# MDR32F1QI register map
Vendor: Milandr; File version: 1.0
CPU: CM1 r0p0, little endian, no MPU, no FPU, 3 interrupt priority bits
Registers are 32-bit, read-write, reset 0x0 unless marked. A register's access mark holds for its fields unless they carry their own. Offsets are from the block's base; [hi:lo] are bit positions; {n}, {i} and the like mark numbered series.

## MDR_DAC — DAC
Base 0x40090000; register names take the prefix MDR_DAC_
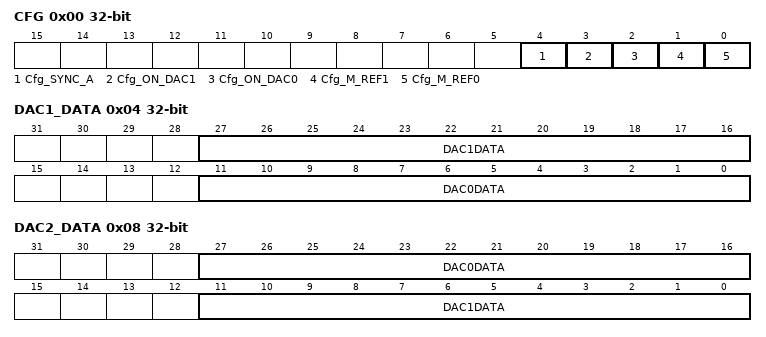
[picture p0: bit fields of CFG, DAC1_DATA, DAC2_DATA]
0x00 CFG — DAC Configuration Register
  [4] Cfg_SYNC_A, [3] Cfg_ON_DAC1, [2] Cfg_ON_DAC0, [1] Cfg_M_REF1, [0] Cfg_M_REF0
0x04 DAC1_DATA
  [27:16] DAC1DATA, [11:0] DAC0DATA
0x08 DAC2_DATA
  [27:16] DAC0DATA, [11:0] DAC1DATA

## MDR_PORTA — PORTA
Base 0x400A8000; register names take the prefix MDR_PORTA_
Same registers: MDR_PORTB 0x400B0000 (register names take the prefix MDR_PORTB_), MDR_PORTC 0x400B8000 (register names take the prefix MDR_PORTC_), MDR_PORTD 0x400C0000 (register names take the prefix MDR_PORTD_), MDR_PORTE 0x400C8000 (register names take the prefix MDR_PORTE_), MDR_PORTF 0x400E8000 (register names take the prefix MDR_PORTF_)
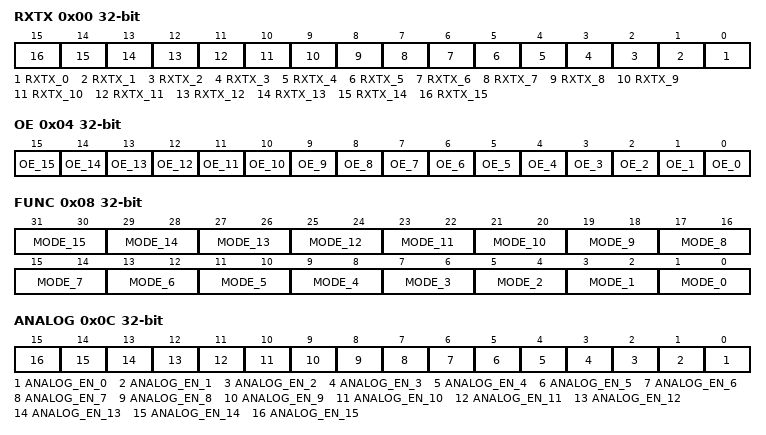
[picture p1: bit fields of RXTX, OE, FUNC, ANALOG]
0x00 RXTX — PORT Data Register
  [n] RXTX_{n} (n=0..15)
0x04 OE — PORT Output Enable Register
  [n] OE_{n} (n=0..15)
0x08 FUNC — PORT Function Register
  [2n+1:2n] MODE_{n} (n=0..15)
0x0C ANALOG — PORT Analog Function Register
  [n] ANALOG_EN_{n} (n=0..15)
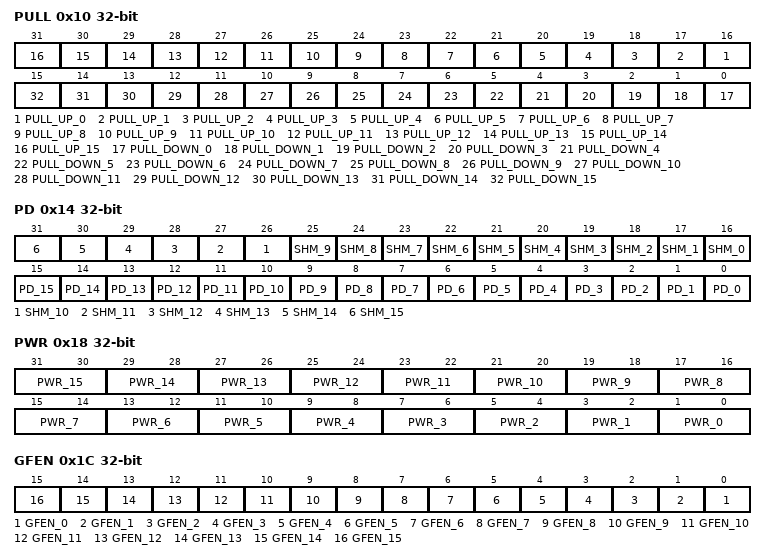
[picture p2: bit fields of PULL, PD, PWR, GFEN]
0x10 PULL — PORT Pull Up/Down Register
  [n+16] PULL_UP_{n} (n=0..15), [n] PULL_DOWN_{n} (n=0..15)
0x14 PD — PORT Driver Mode Register
  [n+16] SHM_{n} (n=0..15), [n] PD_{n} (n=0..15)
0x18 PWR — PORT Power Register
  [2n+1:2n] PWR_{n} (n=0..15)
0x1C GFEN — PORT Filter Configuration Register
  [n] GFEN_{n} (n=0..15)
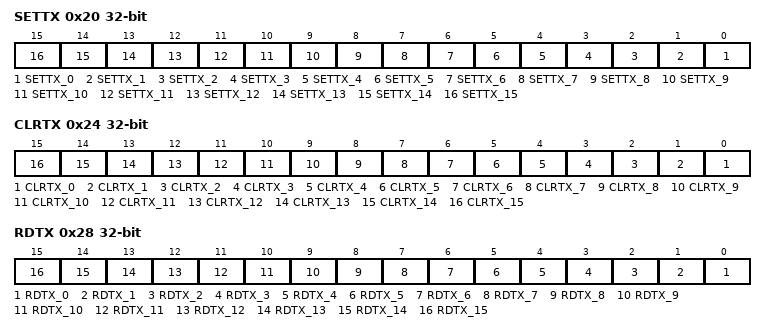
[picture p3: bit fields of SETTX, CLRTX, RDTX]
0x20 SETTX — Set Pin in function PORT
  [n] SETTX_{n} (n=0..15)
0x24 CLRTX — Clear Pin in function PORT
  [n] CLRTX_{n} (n=0..15)
0x28 RDTX ro — Read Pin out in function PORT
  [n] RDTX_{n} rw (n=0..15)

## MDR_ARINC429R — ARINC429R
Base 0x400D0000; register names take the prefix MDR_ARINC429R_
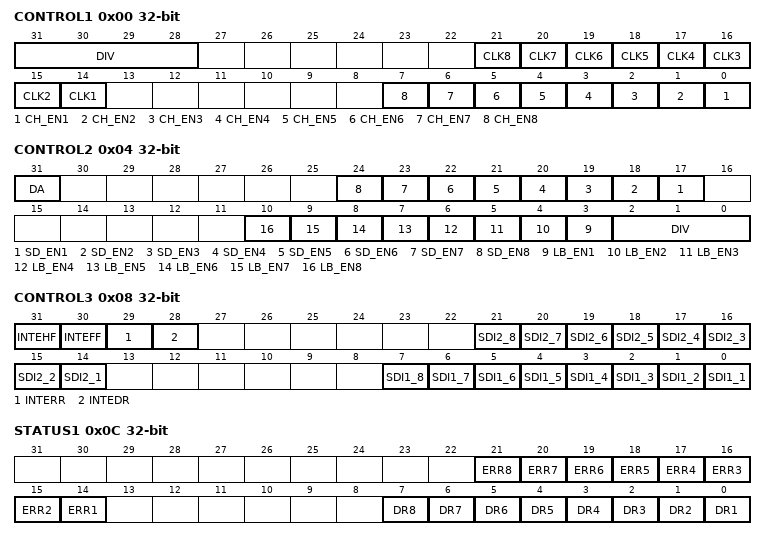
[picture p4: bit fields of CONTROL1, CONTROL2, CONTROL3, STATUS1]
0x00 CONTROL1 — ARINC429R Control1 register
  [31:28] DIV, [n+13] CLK{n} (n=1..8), [n-1] CH_EN{n} (n=1..8)
0x04 CONTROL2 — ARINC429R Control2 register
  [31] DA, [n+16] SD_EN{n} (n=1..8), [n+2] LB_EN{n} (n=1..8), [2:0] DIV
0x08 CONTROL3 — ARINC429R Control3 register
  [31] INTEHF, [30] INTEFF, [29] INTERR, [28] INTEDR, [n+13] SDI2_{n} (n=1..8), [n-1] SDI1_{n} (n=1..8)
0x0C STATUS1 — ARINC429R Status 1 register
  [n+13] ERR{n} (n=1..8), [n-1] DR{n} (n=1..8)
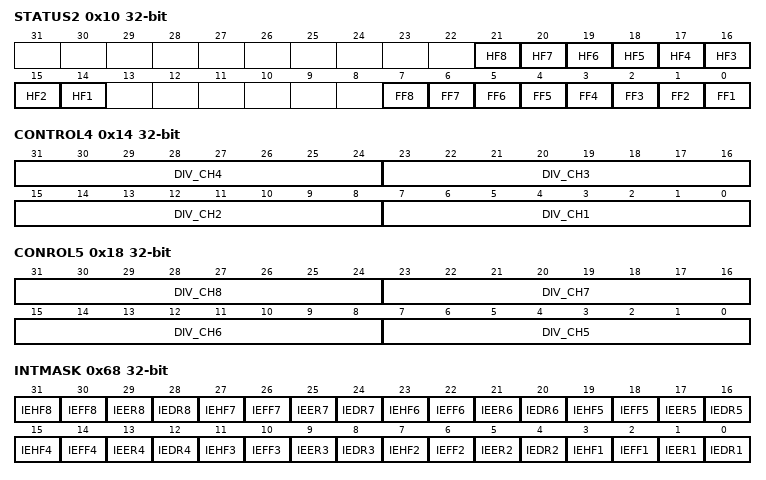
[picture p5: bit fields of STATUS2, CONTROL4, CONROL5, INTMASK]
0x10 STATUS2 — ARINC429R Status 2 register
  [n+13] HF{n} (n=1..8), [n-1] FF{n} (n=1..8)
0x14 CONTROL4 — ARINC429R Control 4 register
  [8n-1:8n-8] DIV_CH{n} (n=1..4)
0x18 CONROL5 — ARINC429R Control 5 register
  [8n-33:8n-40] DIV_CH{n} (n=5..8)
0x1C CHANNEL — ARINC429R Channel register
  [3:0] CHAN
0x20 LABLE — ARINC429R Lable register
0x24 DATA_R — ARINC429R Data_r register
{0x2C+4i} DATA_R{i} (i=1..8) — ARINC429R Data {i} register
0x68 INTMASK — ARINC429R interrupt mask register
  [4n-1] IEHF{n} (n=1..8), [4n-2] IEFF{n} (n=1..8), [4n-3] IEER{n} (n=1..8), [4n-4] IEDR{n} (n=1..8)

## MDR_BKP — BACKUP
Base 0x400D8000; register names take the prefix MDR_BKP_
{0x0+4i} REG_{i:02} (i=0..9) — Backup Register {i}
  [31:0] BKP_REG
0x28 REG_0A — Backup Register 10
  [31:0] BKP_REG
0x2C REG_0B — Backup Register 11
  [31:0] BKP_REG
0x30 REG_0C — Backup Register 12
  [31:0] BKP_REG
0x34 REG_0D — Backup Register 13
  [31:0] BKP_REG
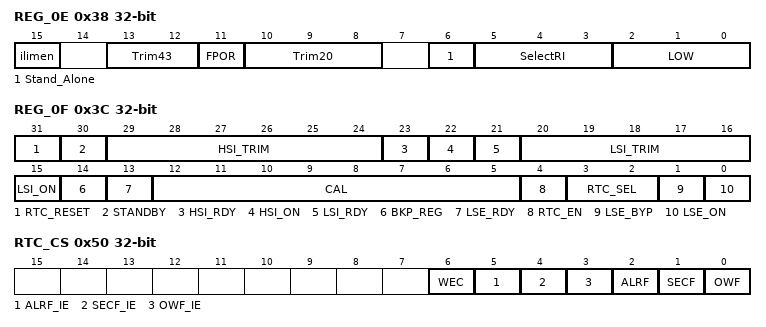
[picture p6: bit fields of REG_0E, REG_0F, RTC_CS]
0x38 REG_0E — Backup Register 14
  [15] ilimen, [13:12] Trim43, [11] FPOR, [10:8] Trim20, [6] Stand_Alone, [5:3] SelectRI, [2:0] LOW
0x3C REG_0F — Backup Register 15
  [31] RTC_RESET, [30] STANDBY, [29:24] HSI_TRIM, [23] HSI_RDY, [22] HSI_ON, [21] LSI_RDY, [20:16] LSI_TRIM, [15] LSI_ON, [14] BKP_REG, [13] LSE_RDY, [12:5] CAL, [4] RTC_EN, [3:2] RTC_SEL, [1] LSE_BYP, [0] LSE_ON
0x40 RTC_CNT — Realtime Clock Counter Register
0x44 RTC_DIV — Realtime Prescaler Counter Register
  [19:0] RTC_DIV
0x48 RTC_PRL — Realtime Prescaler Auto-Reload Value Register
  [19:0] RTC_PRL
0x4C RTC_ALRM — Realtime Alarm Register
0x50 RTC_CS — Backup Realtime clock Register
  [6] WEC, [5] ALRF_IE, [4] SECF_IE, [3] OWF_IE, [2] ALRF, [1] SECF, [0] OWF

## MDR_ARINC429T — ARINC429T
Base 0x400E0000; register names take the prefix MDR_ARINC429T_
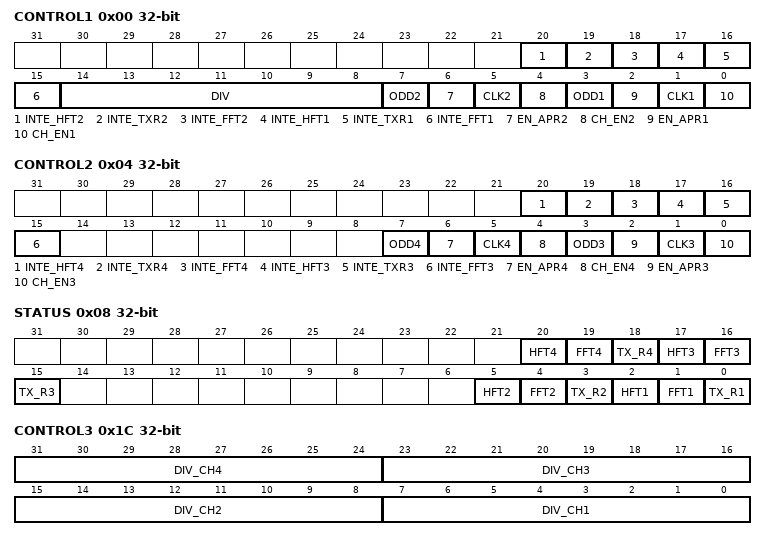
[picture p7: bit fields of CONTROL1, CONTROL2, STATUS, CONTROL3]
0x00 CONTROL1
  [20] INTE_HFT2, [19] INTE_TXR2, [18] INTE_FFT2, [17] INTE_HFT1, [16] INTE_TXR1, [15] INTE_FFT1, [14:8] DIV, [7] ODD2, [6] EN_APR2, [5] CLK2, [4] CH_EN2, [3] ODD1, [2] EN_APR1, [1] CLK1, [0] CH_EN1
0x04 CONTROL2
  [20] INTE_HFT4, [19] INTE_TXR4, [18] INTE_FFT4, [17] INTE_HFT3, [16] INTE_TXR3, [15] INTE_FFT3, [7] ODD4, [6] EN_APR4, [5] CLK4, [4] CH_EN4, [3] ODD3, [2] EN_APR3, [1] CLK3, [0] CH_EN3
0x08 STATUS
  [20] HFT4, [19] FFT4, [18] TX_R4, [17] HFT3, [16] FFT3, [15] TX_R3, [5] HFT2, [4] FFT2, [3] TX_R2, [2] HFT1, [1] FFT1, [0] TX_R1
{0x8+4i} DATA{i}_T (i=1..4)
0x1C CONTROL3
  [8n-1:8n-8] DIV_CH{n} (n=1..4)

## MDR_EBC — EBC
Base 0x400F0000; register names take the prefix MDR_EBC_
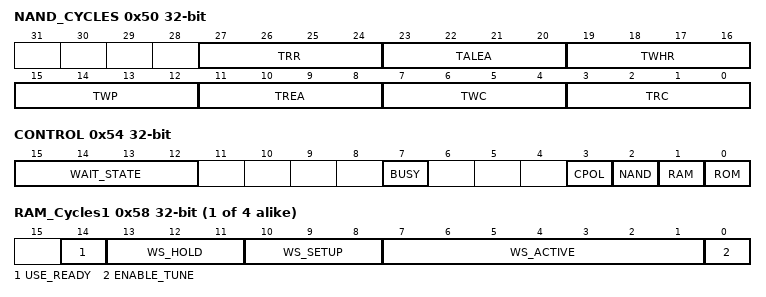
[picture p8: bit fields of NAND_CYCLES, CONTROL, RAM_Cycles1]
0x50 NAND_CYCLES — EBC NAND Timing Register
  [27:24] TRR, [23:20] TALEA, [19:16] TWHR, [15:12] TWP, [11:8] TREA, [7:4] TWC, [3:0] TRC
0x54 CONTROL — EBC Control Register
  [15:12] WAIT_STATE, [7] BUSY, [3] CPOL, [2] NAND, [1] RAM, [0] ROM
{0x54+4i} RAM_Cycles{i} (i=1..4)
  [14] USE_READY, [13:11] WS_HOLD, [10:8] WS_SETUP, [7:1] WS_ACTIVE, [0] ENABLE_TUNE

## MDR_Ethernet — Ethernet
Base 0x30000000; register names take the prefix MDR_Ethernet_
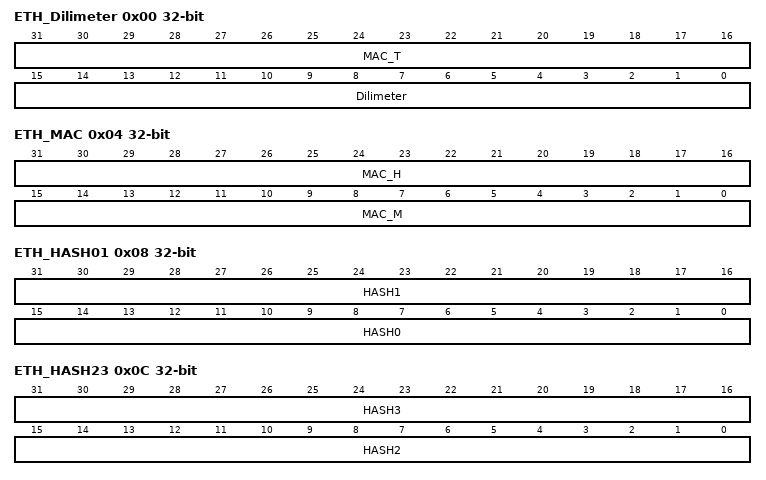
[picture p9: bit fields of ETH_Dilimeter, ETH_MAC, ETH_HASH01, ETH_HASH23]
0x00 ETH_Dilimeter
  [31:16] MAC_T, [15:0] Dilimeter
0x04 ETH_MAC
  [31:16] MAC_H, [15:0] MAC_M
0x08 ETH_HASH01
  [31:16] HASH1, [15:0] HASH0
0x0C ETH_HASH23
  [31:16] HASH3, [15:0] HASH2
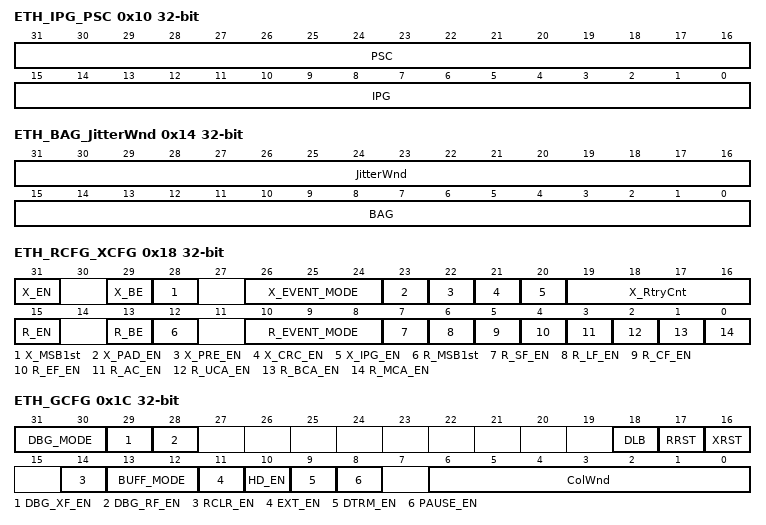
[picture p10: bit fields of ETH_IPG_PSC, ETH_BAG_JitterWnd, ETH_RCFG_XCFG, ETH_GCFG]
0x10 ETH_IPG_PSC
  [31:16] PSC, [15:0] IPG
0x14 ETH_BAG_JitterWnd
  [31:16] JitterWnd, [15:0] BAG
0x18 ETH_RCFG_XCFG
  [31] X_EN, [29] X_BE, [28] X_MSB1st, [26:24] X_EVENT_MODE, [23] X_PAD_EN, [22] X_PRE_EN, [21] X_CRC_EN, [20] X_IPG_EN, [19:16] X_RtryCnt, [15] R_EN, [13] R_BE, [12] R_MSB1st, [10:8] R_EVENT_MODE, [7] R_SF_EN, [6] R_LF_EN, [5] R_CF_EN, [4] R_EF_EN, [3] R_AC_EN, [2] R_UCA_EN, [1] R_BCA_EN, [0] R_MCA_EN
0x1C ETH_GCFG
  [31:30] DBG_MODE, [29] DBG_XF_EN, [28] DBG_RF_EN, [18] DLB, [17] RRST, [16] XRST, [14] RCLR_EN, [13:12] BUFF_MODE, [11] EXT_EN, [10] HD_EN, [9] DTRM_EN, [8] PAUSE_EN, [6:0] ColWnd
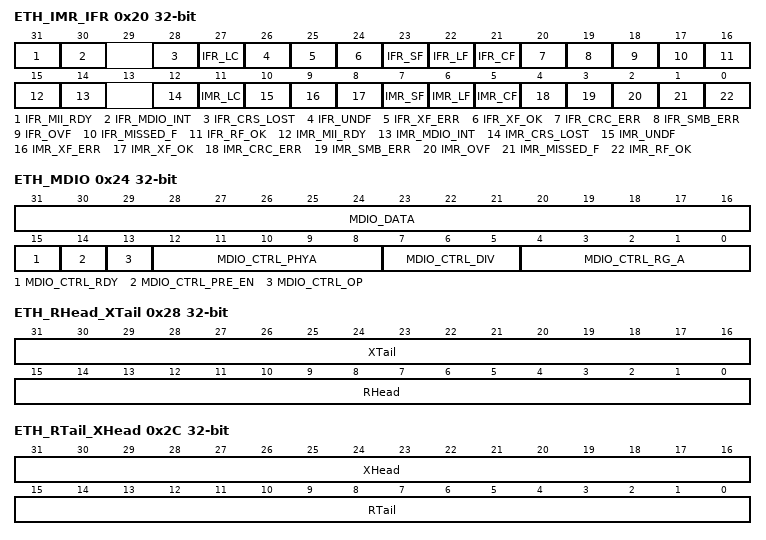
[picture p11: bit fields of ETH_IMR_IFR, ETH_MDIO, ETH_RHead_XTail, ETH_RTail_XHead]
0x20 ETH_IMR_IFR
  [31] IFR_MII_RDY, [30] IFR_MDIO_INT, [28] IFR_CRS_LOST, [27] IFR_LC, [26] IFR_UNDF, [25] IFR_XF_ERR, [24] IFR_XF_OK, [23] IFR_SF, [22] IFR_LF, [21] IFR_CF, [20] IFR_CRC_ERR, [19] IFR_SMB_ERR, [18] IFR_OVF, [17] IFR_MISSED_F, [16] IFR_RF_OK, [15] IMR_MII_RDY, [14] IMR_MDIO_INT, [12] IMR_CRS_LOST, [11] IMR_LC, [10] IMR_UNDF, [9] IMR_XF_ERR, [8] IMR_XF_OK, [7] IMR_SF, [6] IMR_LF, [5] IMR_CF, [4] IMR_CRC_ERR, [3] IMR_SMB_ERR, [2] IMR_OVF, [1] IMR_MISSED_F, [0] IMR_RF_OK
0x24 ETH_MDIO
  [31:16] MDIO_DATA, [15] MDIO_CTRL_RDY, [14] MDIO_CTRL_PRE_EN, [13] MDIO_CTRL_OP, [12:8] MDIO_CTRL_PHYA, [7:5] MDIO_CTRL_DIV, [4:0] MDIO_CTRL_RG_A
0x28 ETH_RHead_XTail
  [31:16] XTail, [15:0] RHead
0x2C ETH_RTail_XHead
  [31:16] XHead, [15:0] RTail
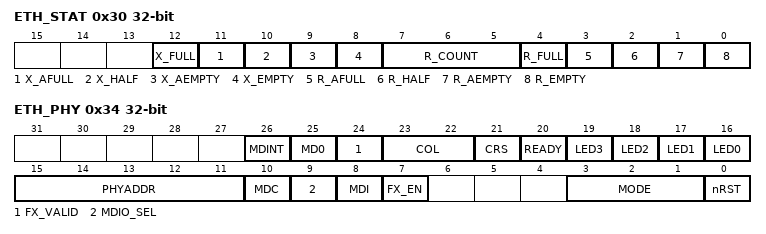
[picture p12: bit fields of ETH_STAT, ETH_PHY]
0x30 ETH_STAT
  [12] X_FULL, [11] X_AFULL, [10] X_HALF, [9] X_AEMPTY, [8] X_EMPTY, [7:5] R_COUNT, [4] R_FULL, [3] R_AFULL, [2] R_HALF, [1] R_AEMPTY, [0] R_EMPTY
0x34 ETH_PHY
  [26] MDINT, [25] MD0, [24] FX_VALID, [23:22] COL, [21] CRS, [20] READY, [n+16] LED{n} (n=0..3), [15:11] PHYADDR, [10] MDC, [9] MDIO_SEL, [8] MDI, [7] FX_EN, [3:1] MODE, [0] nRST
